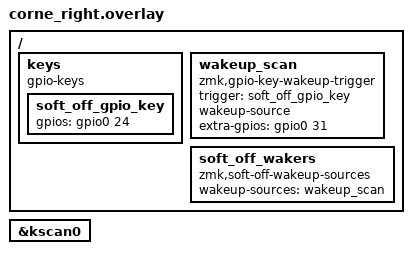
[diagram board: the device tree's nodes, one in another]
/*
 * Wakeup z soft-off tylko przez klawisz RC(1,11) — fizycznie pozycja SQT (symetrycznie do lewej).
 * pro_micro 5 (row 1) = gpio0 24, pro_micro 21 (col 5 prawej) = gpio0 31
 */

/ {
    keys {
        compatible = "gpio-keys";
        soft_off_gpio_key: soft_off_gpio_key {
            gpios = <&gpio0 24 (GPIO_ACTIVE_HIGH | GPIO_PULL_DOWN)>;
        };
    };

    wakeup_scan: wakeup_scan {
        compatible = "zmk,gpio-key-wakeup-trigger";
        trigger = <&soft_off_gpio_key>;
        wakeup-source;
        extra-gpios = <&gpio0 31 GPIO_ACTIVE_HIGH>;
    };

    soft_off_wakers {
        compatible = "zmk,soft-off-wakeup-sources";
        wakeup-sources = <&wakeup_scan>;
    };
};

/* Usuwamy wakeup-source z matrix — inne klawisze nie budzą z soft-off */
&kscan0 {
    /delete-property/ wakeup-source;
};
